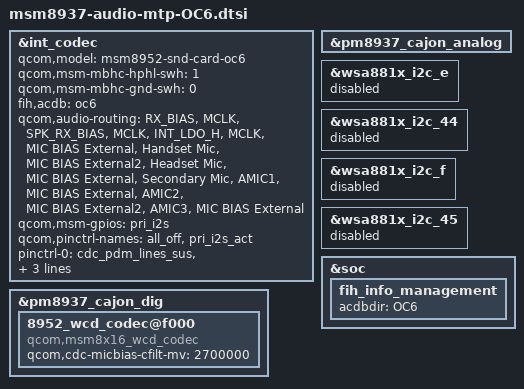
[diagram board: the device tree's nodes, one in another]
/*
 * Copyright (c) 2015-2016, The Linux Foundation. All rights reserved.
 *
 * This program is free software; you can redistribute it and/or modify
 * it under the terms of the GNU General Public License version 2 and
 * only version 2 as published by the Free Software Foundation.
 *
 * This program is distributed in the hope that it will be useful,
 * but WITHOUT ANY WARRANTY; without even the implied warranty of
 * MERCHANTABILITY or FITNESS FOR A PARTICULAR PURPOSE.  See the
 * GNU General Public License for more details.
 */

&int_codec {
	status = "okay";
	qcom,model = "msm8952-snd-card-oc6";
	qcom,msm-micbias2-ext-cap;
	qcom,msm-mbhc-hphl-swh = <1>;
	qcom,msm-mbhc-gnd-swh = <0>;
	//qcom,msm-spk-ext-pa = <&tlmm 3 0>;
	//qcom,msm-hp-switch-en = <&tlmm 94 0>;
	//qcom,msm-hp-switch-in = <&tlmm 95 0>;
	fih,acdb = "oc6";
	qcom,audio-routing =
	"RX_BIAS", "MCLK",
	"SPK_RX_BIAS", "MCLK",
	"INT_LDO_H", "MCLK",
	"MIC BIAS External", "Handset Mic",
	"MIC BIAS External2", "Headset Mic",
	"MIC BIAS External", "Secondary Mic",
	"AMIC1", "MIC BIAS External",
	"AMIC2", "MIC BIAS External2",
	"AMIC3", "MIC BIAS External";
	qcom,msm-gpios =
		"pri_i2s";
	qcom,pinctrl-names =
		"all_off",
		"pri_i2s_act";
	pinctrl-names =
		"all_off",
		"pri_i2s_act";
	pinctrl-0 = <&cdc_pdm_lines_sus &cdc_pdm_lines_2_sus>;
	pinctrl-1 = <&cdc_pdm_lines_act &cdc_pdm_lines_2_act>;
	/delete-property/ pinctrl-2;
	/delete-property/ pinctrl-3;
	/delete-property/ pinctrl-4;
	/delete-property/ pinctrl-5;
	/delete-property/ pinctrl-6;
	/delete-property/ pinctrl-7;

	/delete-property/ qcom,cdc-us-euro-gpios;
	/delete-property/ qcom,hdmi-dba-codec-rx;
	/delete-property/ qcom,msm-micbias2-ext-cap;
};

&pm8937_cajon_dig {
	status = "okay";
	8952_wcd_codec@f000 {
		compatible = "qcom,msm8x16_wcd_codec";
		qcom,cdc-micbias-cfilt-mv = <2700000>;
	};
};


&pm8937_cajon_analog {
	status = "okay";
};

&wsa881x_i2c_e {
	status = "disabled";
};

&wsa881x_i2c_44 {
	status = "disabled";
};

&wsa881x_i2c_f {
	status = "disabled";
};

&wsa881x_i2c_45 {
	status = "disabled";
};

&soc {
	fih_info_management {
		acdbdir="OC6";
	};
};
